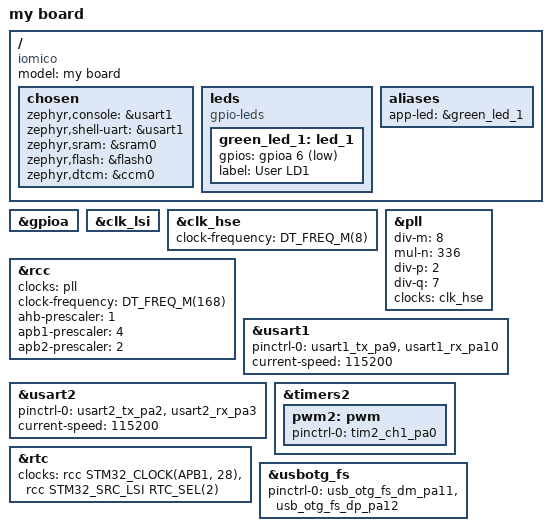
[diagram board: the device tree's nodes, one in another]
/*
 * Copyright (c) 2020 Intel Corporation
 *
 * SPDX-License-Identifier: Apache-2.0
 */

/dts-v1/;
#include <st/f4/stm32f407Xe.dtsi>
#include <st/f4/stm32f407v(e-g)tx-pinctrl.dtsi>
#include <zephyr/dt-bindings/input/input-event-codes.h>

/ {
	model = "my board";
	compatible = "iomico";

	chosen {
		zephyr,console = &usart1;
		zephyr,shell-uart = &usart1;
		zephyr,sram = &sram0;
		zephyr,flash = &flash0;
		zephyr,dtcm = &ccm0;
	};

	leds {
		compatible = "gpio-leds";

		green_led_1: led_1 {
			gpios = <&gpioa 6 GPIO_ACTIVE_LOW>;
			label = "User LD1";
		};
	};

	aliases {
		app-led = &green_led_1;
	};
};

&gpioa {
	status = "okay";
};

&clk_lsi {
	status = "okay";
};

&clk_hse {
	clock-frequency = <DT_FREQ_M(8)>;
	status = "okay";
};

&pll {
	div-m = <8>;
	mul-n = <336>;
	div-p = <2>;
	div-q = <7>;
	clocks = <&clk_hse>;
	status = "okay";
};

&rcc {
	clocks = <&pll>;
	clock-frequency = <DT_FREQ_M(168)>;
	ahb-prescaler = <1>;
	apb1-prescaler = <4>;
	apb2-prescaler = <2>;
};

&usart1 {
	pinctrl-0 = <&usart1_tx_pa9 &usart1_rx_pa10>;
	pinctrl-names = "default";
	current-speed = <115200>;
	status = "okay";
};

&usart2 {
	pinctrl-0 = <&usart2_tx_pa2 &usart2_rx_pa3>;
	pinctrl-names = "default";
	current-speed = <115200>;
	status = "okay";
};

&timers2 {
	status = "okay";

	pwm2: pwm {
		status = "okay";
		pinctrl-0 = <&tim2_ch1_pa0>;
		pinctrl-names = "default";
	};
};

&rtc {
	clocks = <&rcc STM32_CLOCK(APB1, 28)>,
		 <&rcc STM32_SRC_LSI RTC_SEL(2)>;
	status = "okay";
};

zephyr_udc0: &usbotg_fs {
	pinctrl-0 = <&usb_otg_fs_dm_pa11 &usb_otg_fs_dp_pa12>;
	pinctrl-names = "default";
	status = "okay";
};
